# QN908XC register map
Vendor: nxp.com; File version: 1.0
CPU: CM4 r0p1, little endian, no MPU, no FPU, 0x3 interrupt priority bits, 0x0 interrupts
Registers are 32-bit, read-write, reset 0x0 unless marked. A register's access mark holds for its fields unless they carry their own. Offsets are from the block's base; [hi:lo] are bit positions.

## DMA0 — LPC5411x DMA controller
Base 0x40082000
0x00 CTRL — DMA control.
  [0] ENABLE — DMA controller master enable.
    0=DISABLED (Disabled. The DMA controller is disabled. This clears any triggers that were asserted at the point when disabled, but does not prevent re-triggering when the DMA controller is re-enabled.); 1=ENABLED (Enabled. The DMA controller is enabled.)
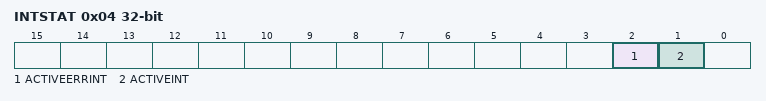
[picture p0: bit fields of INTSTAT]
0x04 INTSTAT ro — Interrupt status.
  [2] ACTIVEERRINT — Summarizes whether any error interrupts are pending.
    0=NOT_PENDING (Not pending. No error interrupts are pending.); 1=PENDING (Pending. At least one error interrupt is pending.)
  [1] ACTIVEINT — Summarizes whether any enabled interrupts (other than error interrupts) are pending.
    0=NOT_PENDING (Not pending. No enabled interrupts are pending.); 1=PENDING (Pending. At least one enabled interrupt is pending.)
0x08 SRAMBASE — SRAM address of the channel configuration table.
  [31:9] OFFSET — Address bits 31:9 of the beginning of the DMA descriptor table. For 18 channels, the table must begin on a 512 byte boundary.
0x20 ENABLESET0 — Channel Enable read and Set for all DMA channels.
  [31:0] ENA — Enable for DMA channels. Bit n enables or disables DMA channel n. The number of bits = number of DMA channels in this device. Other bits are reserved. 0 = disabled. 1 = enabled.
0x28 ENABLECLR0 wo reset not defined — Channel Enable Clear for all DMA channels.
  [31:0] CLR — Writing ones to this register clears the corresponding bits in ENABLESET0. Bit n clears the channel enable bit n. The number of bits = number of DMA channels in this device. Other bits are reserved.
0x30 ACTIVE0 ro — Channel Active status for all DMA channels.
  [31:0] ACT — Active flag for DMA channel n. Bit n corresponds to DMA channel n. The number of bits = number of DMA channels in this device. Other bits are reserved. 0 = not active. 1 = active.
0x38 BUSY0 ro — Channel Busy status for all DMA channels.
  [31:0] BSY — Busy flag for DMA channel n. Bit n corresponds to DMA channel n. The number of bits = number of DMA channels in this device. Other bits are reserved. 0 = not busy. 1 = busy.
0x40 ERRINT0 — Error Interrupt status for all DMA channels.
  [31:0] ERR — Error Interrupt flag for DMA channel n. Bit n corresponds to DMA channel n. The number of bits = number of DMA channels in this device. Other bits are reserved. 0 = error interrupt is not active. 1 = error interrupt is active.
0x48 INTENSET0 — Interrupt Enable read and Set for all DMA channels.
  [31:0] INTEN — Interrupt Enable read and set for DMA channel n. Bit n corresponds to DMA channel n. The number of bits = number of DMA channels in this device. Other bits are reserved. 0 = interrupt for DMA channel is disabled. 1 = interrupt for DMA channel is enabled.
0x50 INTENCLR0 wo reset not defined — Interrupt Enable Clear for all DMA channels.
  [31:0] CLR — Writing ones to this register clears corresponding bits in the INTENSET0. Bit n corresponds to DMA channel n. The number of bits = number of DMA channels in this device. Other bits are reserved.
0x58 INTA0 — Interrupt A status for all DMA channels.
  [31:0] IA — Interrupt A status for DMA channel n. Bit n corresponds to DMA channel n. The number of bits = number of DMA channels in this device. Other bits are reserved. 0 = the DMA channel interrupt A is not active. 1 = the DMA channel interrupt A is active.
0x60 INTB0 — Interrupt B status for all DMA channels.
  [31:0] IB — Interrupt B status for DMA channel n. Bit n corresponds to DMA channel n. The number of bits = number of DMA channels in this device. Other bits are reserved. 0 = the DMA channel interrupt B is not active. 1 = the DMA channel interrupt B is active.
0x68 SETVALID0 wo reset not defined — Set ValidPending control bits for all DMA channels.
  [31:0] SV — SETVALID control for DMA channel n. Bit n corresponds to DMA channel n. The number of bits = number of DMA channels in this device. Other bits are reserved. 0 = no effect. 1 = sets the VALIDPENDING control bit for DMA channel n
0x70 SETTRIG0 wo reset not defined — Set Trigger control bits for all DMA channels.
  [31:0] TRIG — Set Trigger control bit for DMA channel 0. Bit n corresponds to DMA channel n. The number of bits = number of DMA channels in this device. Other bits are reserved. 0 = no effect. 1 = sets the TRIG bit for DMA channel n.
0x78 ABORT0 wo reset not defined — Channel Abort control for all DMA channels.
  [31:0] ABORTCTRL — Abort control for DMA channel 0. Bit n corresponds to DMA channel n. 0 = no effect. 1 = aborts DMA operations on channel n.
